# STM32H7RSxx register map
File version: 0.2
CPU: CM7 r0p1, little endian, MPU, FPU, 4 interrupt priority bits
Registers are 32-bit, read-write, reset 0x0 unless marked. A register's access mark holds for its fields unless they carry their own. Offsets are from the block's base; [hi:lo] are bit positions; {n}, {i} and the like mark numbered series; 'fields as' and 'values as' point back to an identical list; <NAME> marks a mode.

## RCC (part 2 of 3) — Reset and clock control
Base 0x58024400
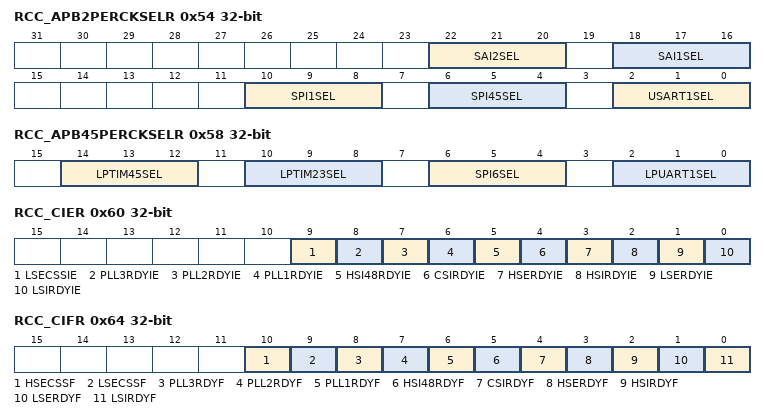
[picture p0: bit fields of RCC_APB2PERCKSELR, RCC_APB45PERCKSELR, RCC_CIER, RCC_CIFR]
0x54 RCC_APB2PERCKSELR — RCC APB2 peripherals kernel clock selection register
  [22:20] SAI2SEL — SAI2 kernel clock source selection Set and reset by software. If the selected clock is the external clock and this clock is stopped, it is not possible to switch to another clock. Refer to Clock switches and gating on page 437 for additional information. others: reserved, the kernel clock is disabled Note: I2S_CKIN is an external clock taken from a pin. spdifrx_symb_ck is the symbol clock generated by the spdifrx (see Figure 51).
    0=pll1_q_ck selected as SAI2 kernel clock (default after reset); 1=pll2_p_ck selected as SAI2 kernel clock; 2=pll3_p_ck selected as SAI2 kernel clock; 3=I2S_CKIN selected as SAI2 kernel clock; 4=per_ck selected as SAI2 kernel clock; 5=spdifrx_symb_ck selected as SAI2 kernel clock
  [18:16] SAI1SEL — SAI1 kernel clock source selection Set and reset by software. If the selected clock is the external clock and this clock is stopped, it is not possible to switch to another clock. Refer to Clock switches and gating on page 437 for additional information. others: reserved, the kernel clock is disabled Note: I2S_CKIN is an external clock taken from a pin.
    0=pll1_q_ck selected as SAI1 kernel clock (default after reset); 1=pll2_p_ck selected as SAI1 kernel clock; 2=pll3_p_ck selected as SAI1 kernel clock; 3=I2S_CKIN selected as SAI1 kernel clock; 4=per_ck selected as SAI1 kernel clock
  [10:8] SPI1SEL — SPI/I2S1 kernel clock source selection Set and reset by software. If the selected clock is the external clock and this clock is stopped, it is not be possible to switch to another clock. Refer to Clock switches and gating on page 437 for additional information. others: reserved, the kernel clock is disabled Note: I2S_CKIN is an external clock taken from a pin.
    0=pll1_q_ck selected as SPI/I2S1 and 7 kernel clock (default after reset); 1=pll2_p_ck selected as SPI/I2S1 and 7 kernel clock; 2=pll3_p_ck selected as SPI/I2S1 and 7 kernel clock; 3=I2S_CKIN selected as SPI/I2S1 and 7 kernel clock; 4=per_ck selected as SPI/I2S1,and 7 kernel clock
  [6:4] SPI45SEL — SPI4 and 5 kernel clock source selection Set and reset by software. others: reserved, the kernel clock is disabled
    0=pclk2 selected as kernel clock (default after reset); 1=pll2_q_ck is selected as kernel clock; 2=pll3_q_ck is selected as kernel clock; 3=hsi_ker_ck is selected as kernel clock; 4=csi_ker_ck is selected as kernel clock; 5=hse_ker_ck is selected as kernel clock
  [2:0] USART1SEL — USART1 kernel clock source selection Set and reset by software. others: reserved, the kernel clock is disabled
    0=pclk2 selected as kernel clock (default after reset); 1=pll2_q_ck selected as kernel clock; 2=pll3_q_ck selected as kernel clock; 3=hsi_ker_ck selected as kernel clock; 4=csi_ker_ck selected as kernel clock; 5=lse_ck selected as kernel clock
0x58 RCC_APB45PERCKSELR — RCC APB4,5 peripherals kernel clock selection register
  [14:12] LPTIM45SEL — LPTIM4, and LPTIM5 kernel clock source selection Set and reset by software. others: reserved, the kernel clock is disabled
    0=pclk4 selected as kernel peripheral clock (default after reset); 1=pll2_p_ck selected as kernel peripheral clock; 2=pll3_r_ck selected as kernel peripheral clock; 3=lse_ck selected as kernel peripheral clock; 4=lsi_ck selected as kernel peripheral clock; 5=per_ck selected as kernel peripheral clock
  [10:8] LPTIM23SEL — LPTIM2 and LPTIM3 kernel clock source selection Set and reset by software. others: reserved, the kernel clock is disabled
    values as LPTIM45SEL
  [6:4] SPI6SEL — SPI/I2S6 kernel clock source selection Set and reset by software. others: reserved, the kernel clock is disabled
    0=pclk4 selected as kernel peripheral clock (default after reset); 1=pll2_q_ck selected as kernel peripheral clock; 2=pll3_q_ck selected as kernel peripheral clock; 3=hsi_ker_ck selected as kernel peripheral clock; 4=csi_ker_ck selected as kernel peripheral clock; 5=hse_ker_ck selected as kernel peripheral clock
  [2:0] LPUART1SEL — LPUART1 kernel clock source selection Set and reset by software. others: reserved, the kernel clock is disabled
    0=pclk4 selected as kernel peripheral clock (default after reset); 1=pll2_q_ck selected as kernel peripheral clock; 2=pll3_q_ck selected as kernel peripheral clock; 3=hsi_ker_ck selected as kernel peripheral clock; 4=csi_ker_ck selected as kernel peripheral clock; 5=lse_ck selected as kernel peripheral clock
0x60 RCC_CIER — RCC clock source interrupt enable register
  [9] LSECSSIE — LSE clock security system interrupt enable Set and reset by software to enable/disable interrupt caused by the clock security system (CSS) on external 32 kHz oscillator.
    0=LSE CSS interrupt disabled (default after reset); 1=LSE CSS interrupt enabled
  [8] PLL3RDYIE — PLL3 ready interrupt enable Set and reset by software to enable/disable interrupt caused by PLL3 lock.
    0=PLL3 lock interrupt disabled (default after reset); 1=PLL3 lock interrupt enabled
  [7] PLL2RDYIE — PLL2 ready interrupt enable Set and reset by software to enable/disable interrupt caused by PLL2 lock.
    0=PLL2 lock interrupt disabled (default after reset); 1=PLL2 lock interrupt enabled
  [6] PLL1RDYIE — PLL1 ready interrupt enable Set and reset by software to enable/disable interrupt caused by PLL1 lock.
    0=PLL1 lock interrupt disabled (default after reset); 1=PLL1 lock interrupt enabled
  [5] HSI48RDYIE — HSI48 ready interrupt enable Set and reset by software to enable/disable interrupt caused by the HSI48 oscillator stabilization.
    0=HSI48 ready interrupt disabled (default after reset); 1=HSI48 ready interrupt enabled
  [4] CSIRDYIE — CSI ready interrupt enable Set and reset by software to enable/disable interrupt caused by the CSI oscillator stabilization.
    0=CSI ready interrupt disabled (default after reset); 1=CSI ready interrupt enabled
  [3] HSERDYIE — HSE ready interrupt enable Set and reset by software to enable/disable interrupt caused by the HSE oscillator stabilization.
    0=HSE ready interrupt disabled (default after reset); 1=HSE ready interrupt enabled
  [2] HSIRDYIE — HSI ready interrupt enable Set and reset by software to enable/disable interrupt caused by the HSI oscillator stabilization.
    0=HSI ready interrupt disabled (default after reset); 1=HSI ready interrupt enabled
  [1] LSERDYIE — LSE ready interrupt enable Set and reset by software to enable/disable interrupt caused by the LSE oscillator stabilization.
    0=LSE ready interrupt disabled (default after reset); 1=LSE ready interrupt enabled
  [0] LSIRDYIE — LSI ready interrupt enable Set and reset by software to enable/disable interrupt caused by the LSI oscillator stabilization.
    0=LSI ready interrupt disabled (default after reset); 1=LSI ready interrupt enabled
0x64 RCC_CIFR ro — RCC clock source interrupt flag register
  [10] HSECSSF — HSE clock security system interrupt flag Reset by software by writing HSECSSC bit. Set by hardware in case of HSE clock failure.
    0=no clock security interrupt caused by HSE clock failure (default after reset); 1=clock security interrupt caused by HSE clock failure
  [9] LSECSSF — LSE clock security system interrupt flag Reset by software by writing LSECSSC bit. Set by hardware when a failure is detected on the external 32 kHz oscillator and LSECSSIE is set.
    0=no failure detected on the external 32 kHz oscillator (default after reset); 1=failure detected on the external 32 kHz oscillator
  [8] PLL3RDYF — PLL3 ready interrupt flag Reset by software by writing PLL3RDYC bit. Set by hardware when the PLL3 locks and PLL3RDYIE is set.
    0=no clock ready interrupt caused by PLL3 lock (default after reset); 1=clock ready interrupt caused by PLL3 lock
  [7] PLL2RDYF — PLL2 ready interrupt flag Reset by software by writing PLL2RDYC bit. Set by hardware when the PLL2 locks and PLL2RDYIE is set.
    0=no clock ready interrupt caused by PLL2 lock (default after reset); 1=clock ready interrupt caused by PLL2 lock
  [6] PLL1RDYF — PLL1 ready interrupt flag Reset by software by writing PLL1RDYC bit. Set by hardware when the PLL1 locks and PLL1RDYIE is set.
    0=no clock ready interrupt caused by PLL1 lock (default after reset); 1=clock ready interrupt caused by PLL1 lock
  [5] HSI48RDYF — HSI48 ready interrupt flag Reset by software by writing HSI48RDYC bit. Set by hardware when the HSI48 clock becomes stable and HSI48RDYIE is set.
    0=no clock ready interrupt caused by the HSI48 oscillator (default after reset); 1=clock ready interrupt caused by the HSI48 oscillator
  [4] CSIRDYF — CSI ready interrupt flag Reset by software by writing CSIRDYC bit. Set by hardware when the CSI clock becomes stable and CSIRDYIE is set.
    0=no clock ready interrupt caused by the CSI (default after reset); 1=clock ready interrupt caused by the CSI
  [3] HSERDYF — HSE ready interrupt flag Reset by software by writing HSERDYC bit. Set by hardware when the HSE clock becomes stable and HSERDYIE is set.
    0=no clock ready interrupt caused by the HSE (default after reset); 1=clock ready interrupt caused by the HSE
  [2] HSIRDYF — HSI ready interrupt flag Reset by software by writing HSIRDYC bit. Set by hardware when the HSI clock becomes stable and HSIRDYIE is set.
    0=no clock ready interrupt caused by the HSI (default after reset); 1=clock ready interrupt caused by the HSI
  [1] LSERDYF — LSE ready interrupt flag Reset by software by writing LSERDYC bit. Set by hardware when the LSE clock becomes stable and LSERDYIE is set.
    0=no clock ready interrupt caused by the LSE (default after reset); 1=clock ready interrupt caused by the LSE
  [0] LSIRDYF — LSI ready interrupt flag Reset by software by writing LSIRDYC bit. Set by hardware when the LSI clock becomes stable and LSIRDYIE is set.
    0=no clock ready interrupt caused by the LSI (default after reset); 1=clock ready interrupt caused by the LSI
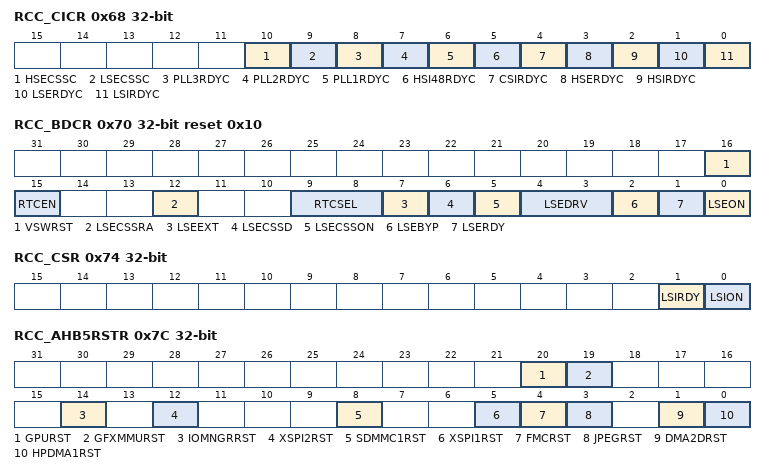
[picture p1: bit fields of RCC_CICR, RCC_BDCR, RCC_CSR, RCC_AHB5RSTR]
0x68 RCC_CICR — RCC clock source interrupt clear register
  [10] HSECSSC — HSE clock security system interrupt clear Set by software to clear HSECSSF. Reset by hardware when clear done.
    0=HSECSSF no effect (default after reset); 1=HSECSSF cleared
  [9] LSECSSC — LSE clock security system interrupt clear Set by software to clear LSECSSF. Reset by hardware when clear done.
    0=LSECSSF no effect (default after reset); 1=LSECSSF cleared
  [8] PLL3RDYC — PLL3 ready interrupt clear Set by software to clear PLL3RDYF. Reset by hardware when clear done.
    0=PLL3RDYF no effect (default after reset); 1=PLL3RDYF cleared
  [7] PLL2RDYC — PLL2 ready interrupt clear Set by software to clear PLL2RDYF. Reset by hardware when clear done.
    0=PLL2RDYF no effect (default after reset); 1=PLL2RDYF cleared
  [6] PLL1RDYC — PLL1 ready interrupt clear Set by software to clear PLL1RDYF. Reset by hardware when clear done.
    0=PLL1RDYF no effect (default after reset); 1=PLL1RDYF cleared
  [5] HSI48RDYC — HSI48 ready interrupt clear Set by software to clear HSI48RDYF. Reset by hardware when clear done.
    0=HSI48RDYF no effect (default after reset); 1=HSI48RDYF cleared
  [4] CSIRDYC — CSI ready interrupt clear Set by software to clear CSIRDYF. Reset by hardware when clear done.
    0=CSIRDYF no effect (default after reset); 1=CSIRDYF cleared
  [3] HSERDYC — HSE ready interrupt clear Set by software to clear HSERDYF. Reset by hardware when clear done.
    0=HSERDYF no effect (default after reset); 1=HSERDYF cleared
  [2] HSIRDYC — HSI ready interrupt clear Set by software to clear HSIRDYF. Reset by hardware when clear done.
    0=HSIRDYF no effect (default after reset); 1=HSIRDYF cleared
  [1] LSERDYC — LSE ready interrupt clear Set by software to clear LSERDYF. Reset by hardware when clear done.
    0=LSERDYF no effect (default after reset); 1=LSERDYF cleared
  [0] LSIRDYC — LSI ready interrupt clear Set by software to clear LSIRDYF. Reset by hardware when clear done.
    0=LSIRDYF no effect (default after reset); 1=LSIRDYF cleared
0x70 RCC_BDCR access per field reset 0x10 — RCC Backup domain control register
  [16] VSWRST rw — VSwitch domain software reset Set and reset by software. To generate a VSW reset, it is recommended to write this bit to 1, then back to 0.
    0=reset not activated (default after Backup domain reset); 1=generates a reset pulse, resetting the entire VSW domain
  [15] RTCEN rw — RTC clock enable Set and reset by software.
    0=rtc_ck disabled (default after Backup domain reset); 1=rtc_ck enabled
  [12] LSECSSRA rw — Re-Arm the LSECSS function Set by software. After a LSE failure detection, the software application can re-enable the LSECSS by writing this bit to 1. Reading this bit returns the written value. Prior to set this bit to 1, LSECSSON must be set to 0. Please refer to Section : CSS on LSE for details.
    0=Writing 0 has no effect (default after Backup domain reset); 1=Writing 1 generates a re-arm pulse for the LSECSS function
  [9:8] RTCSEL rw-once — RTC clock source selection Set by software to select the clock source for the RTC. These bits can be written only one time (except in case of failure detection on LSE). These bits must be written before LSECSSON is enabled. The VSWRST bit can be used to reset them, then it can be written one time again. If HSE is selected as RTC clock, this clock is lost when the system is in Stop mode or in case of a pin reset (NRST).
    0=no clock (default after Backup domain reset); 1=LSE selected as RTC clock; 2=LSI selected as RTC clock; 3=HSE divided by RTCPRE value selected as RTC clock
  [7] LSEEXT rw — low-speed external clock type in Bypass mode Set and reset by software to select the external clock type (analog or digital). The external clock must be enabled with the LSEON bit, to be used by the device. The LSEEXT bit can be written only if the LSE oscillator is disabled.
    0=LSE in analog mode (default after Backup domain reset); 1=LSE in digital mode (do not use if RTC is active)
  [6] LSECSSD ro — LSE clock security system failure detection Set by hardware to indicate when a failure has been detected by the clock security system on the external 32 kHz oscillator.
    0=no failure detected on 32 kHz oscillator (default after Backup domain reset); 1=failure detected on 32 kHz oscillator
  [5] LSECSSON rw — LSE clock security system enable Set by software to enable the clock security system on 32 kHz oscillator. LSECSSON must be enabled after LSE is enabled (LSEON enabled) and ready (LSERDY set by hardware) and after RTCSEL is selected. Once enabled, this bit can only be disabled, After a LSE failure detection (LSECSSD = 1). In that case the software must disable LSECSSON. After a back-up domain reset
    0=CSS on 32 kHz oscillator OFF (default after Backup domain reset); 1=CSS on 32 kHz oscillator ON
  [4:3] LSEDRV rw — LSE oscillator driving capability Set by software to select the driving capability of the LSE oscillator.
    0=lowest drive (default after Backup domain reset); 1=medium-low drive; 2=medium-high drive; 3=highest drive
  [2] LSEBYP rw — LSE oscillator bypass Set and reset by software to bypass oscillator in debug mode. This bit must not be written when the LSE is enabled (by LSEON) or ready (LSERDY = 1)
    0=LSE oscillator not bypassed (default after Backup domain reset); 1=LSE oscillator bypassed
  [1] LSERDY ro — LSE oscillator ready Set and reset by hardware to indicate when the LSE is stable. This bit needs 6 cycles of lse_ck clock to fall down after LSEON has been set to 0.
    0=LSE oscillator not ready (default after Backup domain reset); 1=LSE oscillator ready
  [0] LSEON rw — LSE oscillator enabled Set and reset by software.
    0=LSE oscillator OFF (default after Backup domain reset); 1=LSE oscillator ON
0x74 RCC_CSR access per field — RCC clock control and status register
  [1] LSIRDY ro — LSI oscillator ready Set and reset by hardware to indicate when the low-speed internal RC oscillator is stable. This bit needs 3 cycles of lsi_ck clock to fall down after LSION has been set to 0. This bit can be set even when LSION is not enabled if there is a request for LSI clock by the clock security system on LSE or by the low-speed watchdog or by the RTC.
    0=LSI clock is not ready (default after reset); 1=LSI clock is ready
  [0] LSION rw — LSI oscillator enable Set and reset by software.
    0=LSI is OFF (default after reset); 1=LSI is ON
0x7C RCC_AHB5RSTR — RCC AHB5 peripheral reset register
  [all] fields
    0=reset is released (default after reset); 1=reset is asserted
  [20] GPURST — GPU block reset Set and reset by software.
  [19] GFXMMURST — GFXMMU block reset Set and reset by software.
  [14] IOMNGRRST — XSPIM reset Set and reset by software.
  [12] XSPI2RST — XSPI2 and MCE2 blocks reset Set and reset by software. The hardware prevents writing this bit if XSPICKP = 1.
  [8] SDMMC1RST — SDMMC1 and DB_SDMMC1 blocks reset Set and reset by software.
  [5] XSPI1RST — XSPI1 and MCE1 blocks reset Set and reset by software. The hardware prevents writing this bit if XSPICKP = 1.
  [4] FMCRST — FMC and MCE3 blocks reset Set and reset by software. The hardware prevents writing this bit if FMCCKP = 1.
  [3] JPEGRST — JPEG block reset Set and reset by software.
  [1] DMA2DRST — DMA2D block reset Set and reset by software.
  [0] HPDMA1RST — HPDMA1 block reset Set and reset by software.
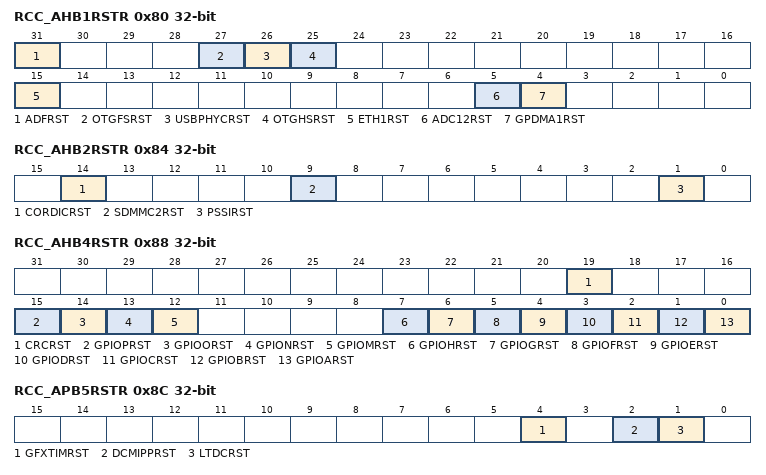
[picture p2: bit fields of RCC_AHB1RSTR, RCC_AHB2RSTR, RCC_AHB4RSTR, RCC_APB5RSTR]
0x80 RCC_AHB1RSTR — RCC AHB1 peripheral reset register
  [31] ADFRST — ADF block reset Set and reset by software.
    0=does not reset ADF block (default after reset); 1=resets ADF block
  [27] OTGFSRST — OTGFS block reset Set and reset by software.
    0=does not reset OTGFS block (default after reset); 1=resets OTGFS block
  [26] USBPHYCRST — USBPHYC block reset Set and reset by software.
    0=does not reset USBPHYC block (default after reset); 1=resets USBPHYC block
  [25] OTGHSRST — OTGHS block reset Set and reset by software.
    0=does not reset OTGHS block (default after reset); 1=resets OTGHS block
  [15] ETH1RST — ETH1 block reset Set and reset by software.
    0=does not reset ETH1 block (default after reset); 1=resets ETH1 block
  [5] ADC12RST — ADC1 and 2 blocks reset Set and reset by software.
    0=does not reset ADC1 and 2 blocks (default after reset); 1=resets ADC1 and 2 blocks
  [4] GPDMA1RST — GPDMA1 blocks reset Set and reset by software.
    0=does not reset GPDMA1 block (default after reset); 1=resets GPDMA1 block
0x84 RCC_AHB2RSTR — RCC AHB2 peripheral reset register
  [14] CORDICRST — CORDIC reset Set and reset by software.
    0=does not reset CORDIC block (default after reset); 1=resets CORDIC block
  [9] SDMMC2RST — SDMMC2 and SDMMC2 delay blocks reset Set and reset by software.
    0=does not reset SDMMC2 and SDMMC2 delay blocks (default after reset); 1=resets SDMMC2 and SDMMC2 delay blocks
  [1] PSSIRST — PSSI block reset Set and reset by software.
    0=does not reset PSSI block (default after reset); 1=resets PSSI block
0x88 RCC_AHB4RSTR — RCC AHB4 peripheral reset register
  [19] CRCRST — CRC block reset Set and reset by software.
    0=does not reset the CRC block (default after reset); 1=resets the CRC block
  [15] GPIOPRST — GPIOP block reset Set and reset by software.
    0=does not reset the GPIOP block (default after reset); 1=resets the GPIOP block
  [14] GPIOORST — GPIOO block reset Set and reset by software.
    0=does not reset the GPIOO block (default after reset); 1=resets the GPIOO block
  [13] GPIONRST — GPION block reset Set and reset by software.
    0=does not reset the GPION block (default after reset); 1=resets the GPION block
  [12] GPIOMRST — GPIOM block reset Set and reset by software.
    0=does not reset the GPIOM block (default after reset); 1=resets the GPIOM block
  [7] GPIOHRST — GPIOH block reset Set and reset by software.
    0=does not reset the GPIOH block (default after reset); 1=resets the GPIOH block
  [6] GPIOGRST — GPIOG block reset Set and reset by software.
    0=does not reset the GPIOG block (default after reset); 1=resets the GPIOG block
  [5] GPIOFRST — GPIOF block reset Set and reset by software.
    0=does not reset the GPIOF block (default after reset); 1=resets the GPIOF block
  [4] GPIOERST — GPIOE block reset Set and reset by software.
    0=does not reset the GPIOE block (default after reset); 1=resets the GPIOE block
  [3] GPIODRST — GPIOD block reset Set and reset by software.
    0=does not reset the GPIOD block (default after reset); 1=resets the GPIOD block
  [2] GPIOCRST — GPIOC block reset Set and reset by software.
    0=does not reset the GPIOC block (default after reset); 1=resets the GPIOC block
  [1] GPIOBRST — GPIOB block reset Set and reset by software.
    0=does not reset the GPIOB block (default after reset); 1=resets the GPIOB block
  [0] GPIOARST — GPIOA block reset Set and reset by software.
    0=does not reset the GPIOA block (default after reset); 1=resets the GPIOA block
0x8C RCC_APB5RSTR — RCC APB5 peripheral reset register
  [4] GFXTIMRST — GFXTIM block reset Set and reset by software.
    0=does not reset the GFXTIM block (default after reset); 1=resets the GFXTIM block
  [2] DCMIPPRST — DCMIPP block reset Set and reset by software.
    0=does not reset the DCMIPP block (default after reset); 1=resets the DCMIPP block
  [1] LTDCRST — LTDC block reset Set and reset by software.
    0=does not reset the LTDC block (default after reset); 1=resets the LTDC block
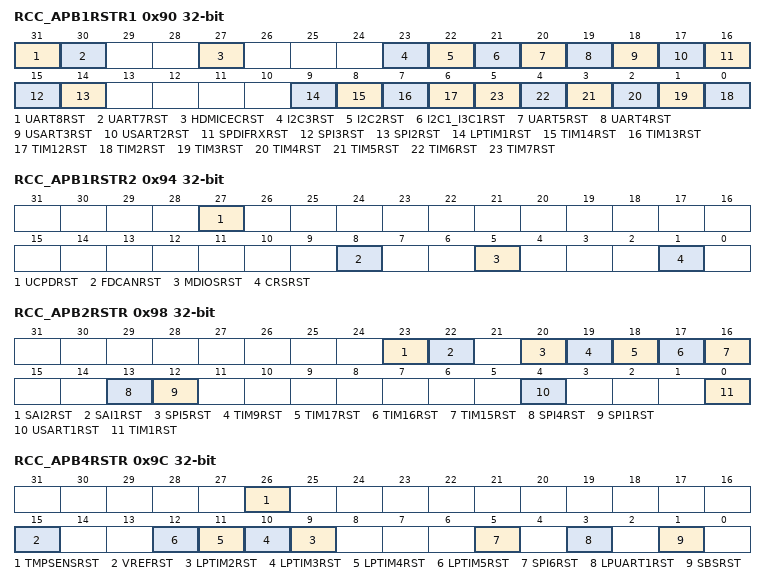
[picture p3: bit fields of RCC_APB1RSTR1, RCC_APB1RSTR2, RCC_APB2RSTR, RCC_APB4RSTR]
0x90 RCC_APB1RSTR1 — RCC APB1 peripheral reset register 1
  [31] UART8RST — UART8 block reset Set and reset by software.
    0=does not reset the UART8 block (default after reset); 1=resets the UART8 block
  [30] UART7RST — UART7 block reset Set and reset by software.
    0=does not reset the UART7 block (default after reset); 1=resets the UART7 block
  [27] HDMICECRST — HDMI-CEC block reset Set and reset by software.
    0=does not reset the HDMI-CEC block (default after reset); 1=resets the HDMI-CEC block
  [23] I2C3RST — I2C3 block reset Set and reset by software.
    0=does not reset the I2C3 block (default after reset); 1=resets the I2C3 block
  [22] I2C2RST — I2C2 block reset Set and reset by software.
    0=does not reset the I2C2 block (default after reset); 1=resets the I2C2 block
  [21] I2C1_I3C1RST — I2C1/I3C1 block reset Set and reset by software.
    0=does not reset the I2C1/I3C1 block (default after reset); 1=resets the I2C1/I3C1 block
  [20] UART5RST — UART5 block reset Set and reset by software.
    0=does not reset the UART5 block (default after reset); 1=resets the UART5 block
  [19] UART4RST — UART4 block reset Set and reset by software.
    0=does not reset the UART4 block (default after reset); 1=resets the UART4 block
  [18] USART3RST — USART3 block reset Set and reset by software.
    0=does not reset the USART3 block (default after reset); 1=resets the USART3 block
  [17] USART2RST — USART2 block reset Set and reset by software.
    0=does not reset the USART2 block (default after reset); 1=resets the USART2 block
  [16] SPDIFRXRST — SPDIFRX block reset Set and reset by software.
    0=does not reset the SPDIFRX block (default after reset); 1=resets the SPDIFRX block
  [15] SPI3RST — SPI2S3 block reset Set and reset by software.
    0=does not reset the SPI2S3 block (default after reset); 1=resets the SPI2S3 block
  [14] SPI2RST — SPI2S2 block reset Set and reset by software.
    0=does not reset the SPI2S2 block (default after reset); 1=resets the SPI2S2 block
  [9] LPTIM1RST — LPTIM1 block reset Set and reset by software.
    0=does not reset the LPTIM1 block (default after reset); 1=resets the LPTIM1 block
  [8] TIM14RST — TIM14 block reset Set and reset by software.
    0=does not reset the TIM14 block (default after reset); 1=resets the TIM14 block
  [7] TIM13RST — TIM13 block reset Set and reset by software.
    0=does not reset the TIM13 block (default after reset); 1=resets the TIM13 block
  [6] TIM12RST — TIM12 block reset Set and reset by software.
    0=does not reset the TIM12 block (default after reset); 1=resets the TIM12 block
  [n-2] TIM{n}RST (n=2..7) — TIM{n} block reset Set and reset by software.
    0=does not reset the TIM{n} block (default after reset); 1=resets the TIM{n} block
0x94 RCC_APB1RSTR2 — RCC APB1 peripheral reset register 2
  [27] UCPDRST — UCPD block reset Set and reset by software.
    0=does not reset the UCPD block (default after reset); 1=resets the UCPD block
  [8] FDCANRST — FDCAN block reset Set and reset by software.
    0=does not reset the FDCAN block (default after reset); 1=resets the FDCAN block
  [5] MDIOSRST — MDIOS block reset Set and reset by software.
    0=does not reset the MDIOS block (default after reset); 1=resets the MDIOS block
  [1] CRSRST — clock recovery system reset Set and reset by software.
    0=does not reset CRS (default after reset); 1=resets CRS
0x98 RCC_APB2RSTR — RCC APB2 peripheral reset register
  [23] SAI2RST — SAI2 block reset Set and reset by software.
    0=does not reset the SAI2 (default after reset); 1=resets the SAI2
  [22] SAI1RST — SAI1 block reset Set and reset by software.
    0=does not reset the SAI1 (default after reset); 1=resets the SAI1
  [20] SPI5RST — SPI5 block reset Set and reset by software.
    0=does not reset the SPI5 block (default after reset); 1=resets the SPI5 block
  [19] TIM9RST — TIM9 block reset Set and reset by software.
    0=does not reset the TIM9 block (default after reset); 1=resets the TIM9 block
  [18] TIM17RST — TIM17 block reset Set and reset by software.
    0=does not reset the TIM17 block (default after reset); 1=resets the TIM17 block
  [17] TIM16RST — TIM16 block reset Set and reset by software.
    0=does not reset the TIM16 block (default after reset); 1=resets the TIM16 block
  [16] TIM15RST — TIM15 block reset Set and reset by software.
    0=does not reset the TIM15 block (default after reset); 1=resets the TIM15 block
  [13] SPI4RST — SPI4 block reset Set and reset by software.
    0=does not reset the SPI4 block (default after reset); 1=resets the SPI4 block
  [12] SPI1RST — SPI2S1 block reset Set and reset by software.
    0=does not reset the SPI2S1 block (default after reset); 1=resets the SPI2S1 block
  [4] USART1RST — USART1 block reset Set and reset by software.
    0=does not reset the USART1 block (default after reset); 1=resets the USART1 block
  [0] TIM1RST — TIM1 block reset Set and reset by software.
    0=does not reset the TIM1 block (default after reset); 1=resets the TIM1 block
0x9C RCC_APB4RSTR — RCC APB4 peripheral reset register
  [26] TMPSENSRST — TMPSENS block reset Set and reset by software.
    0=does not reset the TMPSENS block (default after reset); 1=resets the TMPSENS block
  [15] VREFRST — VREF block reset Set and reset by software.
    0=does not reset the VREF block (default after reset); 1=resets the VREF block
  [n+7] LPTIM{n}RST (n=2..5) — LPTIM{n} block reset Set and reset by software.
    0=does not reset the LPTIM{n} block (default after reset); 1=resets the LPTIM{n} block
  [5] SPI6RST — SPI/I2S6 block reset Set and reset by software.
    0=does not reset the SPI/I2S6 block (default after reset); 1=resets the SPI/I2S6 block
  [3] LPUART1RST — LPUART1 block reset Set and reset by software.
    0=does not reset the LPUART1 block (default after reset); 1=resets the LPUART1 block
  [1] SBSRST — SBS block reset Set and reset by software.
    0=does not reset the SBS block (default after reset); 1=resets the SBS block
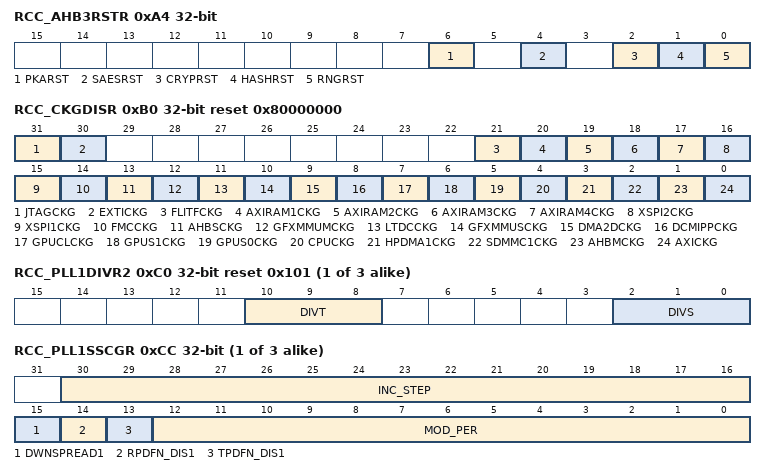
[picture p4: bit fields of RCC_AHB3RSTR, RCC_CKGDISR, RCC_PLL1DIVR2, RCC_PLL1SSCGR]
0xA4 RCC_AHB3RSTR — RCC AHB3 peripheral reset register
  [6] PKARST — PKA block reset Set and reset by software.
    0=does not reset PKA block (default after reset); 1=resets PKA block
  [4] SAESRST — SAES block reset Set and reset by software.
    0=does not reset SAES block (default after reset); 1=resets SAES block
  [2] CRYPRST — CRYP block reset Set and reset by software.
    0=does not reset CRYP block (default after reset); 1=resets CRYP block
  [1] HASHRST — HASH block reset Set and reset by software.
    0=does not reset HASH block (default after reset); 1=resets HASH block
  [0] RNGRST — random number generator block reset Set and reset by software.
    0=does not reset RNG block (default after reset); 1=resets RNG block
0xB0 RCC_CKGDISR reset 0x80000000 — RCC AXI clocks gating disable register
  [31] JTAGCKG — JTAG automatic clock gating disabling This bit is set and reset by software.
    0=The clock gating is enabled. The clock is disabled except if a JTAG connection has been detected 1: The clock gating is disabled. The clock is always enabled. (default after reset)
  [30] EXTICKG — EXTI clock gating disable This bit is set and reset by software.
    0=The clock gating is enabled. The clock is enabled after an event detection and stopped again when the event flag is cleared. (default after reset); 1=The clock gating is disabled. The clock is always enabled.
  [21] FLITFCKG — AXI slave Flash interface (FLIFT) clock gating disable This bit is set and reset by software.
    0=The clock gating is enabled. The clock of the AXI slave port connected to the FLITF is enabled on bus transaction request. (default after reset); 1=The clock gating is disabled. The clock is always enabled.
  [20] AXIRAM1CKG — AXI slave SRAM1 / error code correction (ECC) clock gating disable This bit is set and reset by software.
    0=The clock gating is enabled. The clock of the AXI slave port connected to the SRAM1 is enabled on bus transaction request. (default after reset); 1=The clock gating is disabled. The clock is always enabled.
  [19] AXIRAM2CKG — AXI slave SRAM2 clock gating disable This bit is set and reset by software.
    0=The clock gating is enabled. The clock of the AXI slave port connected to the SRAM2 is enabled on bus transaction request. (default after reset); 1=The clock gating is disabled. The clock is always enabled.
  [18] AXIRAM3CKG — AXI matrix slave SRAM3 clock gating disable This bit is set and reset by software.
    0=The clock gating is enabled. The clock of the AXI slave port connected to the SRAM3 is enabled on bus transaction request. (default after reset); 1=The clock gating is disabled. The clock is always enabled.
  [17] AXIRAM4CKG — AXI matrix slave SRAM4 clock gating disable This bit is set and reset by software.
    0=The clock gating is enabled. The clock of the AXI slave port connected to the SRAM4 is enabled on bus transaction request. (default after reset); 1=The clock gating is disabled. The clock is always enabled.
  [16] XSPI2CKG — AXI slave XSPI2 and MCE2 clock gating disable This bit is set and reset by software.
    0=The clock gating is enabled. The clock of the AXI slave port connected to the XSPI2 and MCE2 is enabled on bus transaction request. (default after reset); 1=The clock gating is disabled. The clock is always enabled.
  [15] XSPI1CKG — AXI slave XSPI1 and MCE1 clock gating disable This bit is set and reset by software.
    0=The clock gating is enabled. The clock of the AXI slave port connected to the XSPI1 and MCE1 is enabled on bus transaction request. (default after reset); 1=The clock gating is disabled. The clock is always enabled.
  [14] FMCCKG — AXI slave FMC and MCE3 clock gating disable This bit is set and reset by software.
    0=The clock gating is enabled. The clock of the AXI slave port connected to the FMC and MCE3 is enabled on bus transaction request. (default after reset); 1=The clock gating is disabled. The clock is always enabled.
  [13] AHBSCKG — AXI slave AHB clock gating disable This bit is set and reset by software.
    0=The clock gating is enabled. The AXI matrix slave AHB clock is enabled on bus transaction request. (default after reset); 1=The clock gating is disabled. The clock is always enabled
  [12] GFXMMUMCKG — AXI master GFXMMU clock gating disable This bit is set and reset by software.
    0=The clock gating is enabled. The clock of the AXI master port connected to the GFXMMU is enabled on bus transaction request. (default after reset); 1=The clock gating is disabled. The clock is always enabled
  [11] LTDCCKG — AXI master LTDC clock gating disable This bit is set and reset by software.
    0=The clock gating is enabled. The clock of the AXI master port connected to the LTDC is enabled on bus transaction request. (default after reset); 1=The clock gating is disabled. The clock is always enabled.
  [10] GFXMMUSCKG — AXI matrix slave GFXMMU clock gating disable This bit is set and reset by software.
    0=The clock gating is enabled. The clock of the AXI slave port connected to the GFXMMU is enabled on bus transaction request. (default after reset); 1=The clock gating is disabled. The clock is always enabled
  [9] DMA2DCKG — AXI master DMA2D clock gating disable This bit is set and reset by software.
    0=The clock gating is enabled. The clock of the AXI master port connected to the DMA2D is enabled on bus transaction request. (default after reset); 1=The clock gating is disabled. The clock is always enabled
  [8] DCMIPPCKG — AXI master DCMIPP clock gating disable This bit is set and reset by software.
    0=The clock gating is enabled. The clock of the AXI master port connected to the DCMIPP is enabled on bus transaction request. (default after reset); 1=The clock gating is disabled. The clock is always enabled.
  [7] GPUCLCKG — AXI master cache GPU clock gating disable This bit is set and reset by software.
    0=The clock gating is enabled. The clock of the AXI master port connected to the GPU I-Cache is enabled on bus transaction request. (default after reset); 1=The clock gating is disabled. The clock is always enabled.
  [6] GPUS1CKG — AXI master 1 GPU clock gating disable This bit is set and reset by software.
    0=The clock gating is enabled. The clock of the AXI master port connected to the GPU port 1 is enabled on bus transaction request. (default after reset); 1=The clock gating is disabled. The clock is always enabled.
  [5] GPUS0CKG — AXI master 0 GPU clock gating disable This bit is set and reset by software.
    0=The clock gating is enabled. The clock of the AXI master port connected to the GPU port 0 is enabled on bus transaction request. (default after reset); 1=The clock gating is disabled. The clock is always enabled.
  [4] CPUCKG — AXI master CPU clock gating disable This bit is set and reset by software.
    0=The clock gating is enabled. The clock of the AXI master port connected to the CPU is enabled on bus transaction request. (default after reset); 1=The clock gating is disabled. The clock is always enabled.
  [3] HPDMA1CKG — AXI master HPDMA1 clock gating disable This bit is set and reset by software.
    0=The clock gating is enabled. The clock of the AXI master port connected to the HPDMA1 is enabled on bus transaction request. (default after reset); 1=The clock gating is disabled. The clock is always enabled
  [2] SDMMC1CKG — AXI master SDMMC1 clock gating disable This bit is set and reset by software.
    0=The clock gating is enabled. The clock of the AXI master port connected to SDMMC1 is enabled on bus transaction request. (default after reset); 1=The clock gating is disabled. The clock is always enabled.
  [1] AHBMCKG — AXI master AHB clock gating disable This bit is set and reset by software.
    0=The clock gating is enabled. The clock of the AXI master port connected to the AHB interconnect is enabled on bus transaction request. (default after reset); 1=The clock gating is disabled. The clock is always enabled.
  [0] AXICKG — AXI interconnect matrix clock gating disable This bit is set and reset by software.
    0=The clock gating is enabled. The AXI interconnect matrix clock is enabled on bus transaction request. (default after reset); 1=The clock gating is disabled. The clock is always enabled
{0xBC+4i} RCC_PLL{i}DIVR2 reset 0x101 (i=1..3) — RCC PLL{i} dividers configuration register 2
  [10:8] DIVT — PLL{i} DIVT division factor Set and reset by software to control the frequency of the pll{i}_t_ck clock. This post-divider performs divisions with 50% duty-cycle. The duty-cycle of 50% is guaranteed only in the following conditions: With VCOL, if (DIVT+1) is even, With VCOH, for all DIVT values These bits can be written only when the PLL{i}DIVTEN = 0.
    0=pll{i}_t_ck = vco{i}_ck; 1=pll{i}_t_ck = vco{i}_ck / 2 (default after reset); {v}=pll{i}_t_ck = vco{i}_ck / {v+1} (v=2..7)
  [2:0] DIVS — PLL{i} DIVS division factor Set and reset by software to control the frequency of the pll{i}_s_ck clock. This post-divider performs divisions with 50% duty-cycle. The duty-cycle of 50% is guaranteed only in the following conditions: With VCOL, if (DIVS+1) is even, With VCOH, for all DIVS values These bits can be written only when the PLL{i}DIVSEN = 0.
    0=pll{i}_s_ck = vco{i}_ck; 1=pll{i}_s_ck = vco{i}_ck / 2 (default after reset); {v}=pll{i}_s_ck = vco{i}_ck / {v+1} (v=2..7)
{0xC8+4i} RCC_PLL{i}SSCGR (i=1..3) — RCC PLL{i} Spread Spectrum Clock Generator register
  [30:16] INC_STEP — Modulation Depth Adjustment for PLL{i} Set and reset by software to adjust the modulation depth of the clock spreading generator.
  [15] DWNSPREAD{i} — Spread spectrum clock generator mode for PLL{i} Set and reset by software to select the clock spreading mode.
    0=Center-spread modulation selected (default after reset); 1=Down-spread modulation selected
  [14] RPDFN_DIS{i} — Dithering RPDF noise control for PLL{i} Set and reset by software. This bit is used to enable or disable the injection of a dithering noise into the SSCG modulator. This dithering noise is generated using a rectangular probability density function.
    0=Dithering noise injection enabled (default after reset); 1=Dithering noise injection disabled
  [13] TPDFN_DIS{i} — Dithering TPDF noise control for PLL{i} Set and reset by software. This bit is used to enable or disable the injection of a dithering noise into the SSCG modulator. This dithering noise is generated using a triangular probability density function.
    values as RPDFN_DIS{i}
  [12:0] MOD_PER — Modulation Period Adjustment for PLL{i} Set and reset by software to adjust the modulation period of the clock spreading generator.
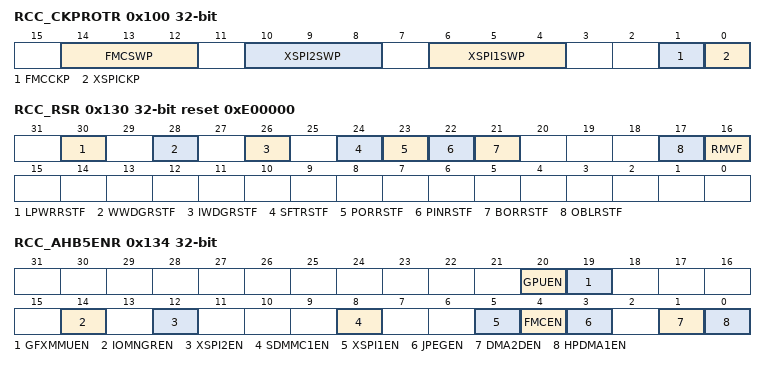
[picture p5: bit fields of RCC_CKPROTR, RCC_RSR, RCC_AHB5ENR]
0x100 RCC_CKPROTR access per field — RCC clock protection register
  [14:12] FMCSWP ro — FMC kernel clock switch position Set by hardware. This field can be used to verify the real position of FMC kernel switch selector.
    0=The switch is in neutral mode and output clock is gated (default after reset); 1=The switch is selecting hclk5; 2=The switch is selecting pll1_q_ck; 3=The switch is selecting pll2_r_ck; 4=The switch is selecting hsi_ker_ck; 5=The switch is in recovery position (hclk5/4)
  [10:8] XSPI2SWP ro — XSPI2 kernel clock switch position Set by hardware. This field can be used to verify the real position of XSPI2 kernel switch selector.
    0=The switch is in neutral mode and output clock is gated (default after reset); 1=The switch is selecting hclk5; 2=The switch is selecting pll2_s_ck; 3=The switch is selecting pll2_t_ck; 4=The switch is in recovery position (hclk5/4)
  [6:4] XSPI1SWP ro — XSPI1 kernel clock switch position Set by hardware. This field can be used to verify the real position of XSPI2 kernel switch selector.
    values as XSPI2SWP
  [1] FMCCKP rw — FMC clock protection Set and cleared by software. When set to 1, this bit prevents disabling accidentally the FMC. The following fields cannot be modified when this bit is set to 1: PLL1ON, PLL2ON, PLL1DIVQEN, PLL2DIVREN, HSEON, HSION, CSION, FMCEN, FMCLPEN, FMCRST.
    0=Clock protection is disabled (default after reset); 1=Clock protection is enabled
  [0] XSPICKP rw — XSPI clock protection Set and cleared by software. When set to 1, this bit prevents disabling accidentally the XSPIs. The following fields cannot be modified when this bit is set to 1: PLL2ON, PLL2DIVSEN, PLL2DIVTEN, HSEON, HSION, CSION, XSPIxEN, OCTOSPIxLPEN, OCTOSPIxRST.
    values as FMCCKP
0x130 RCC_RSR access per field reset 0xE00000 — RCC Reset status register
  [30] LPWRRSTF ro — reset due to illegal Stop or Standby flag Reset by software by writing the RMVF bit. Set by hardware when the CPU goes erroneously in Stop or Standby mode,
    0=no illegal reset occurred (default after power-on reset); 1=illegal Stop or Standby reset occurred
  [28] WWDGRSTF ro — window watchdog reset flag <sup>(1)</sup> Reset by software by writing the RMVF bit. Set by hardware when a window watchdog reset occurs.
    0=no window watchdog reset occurred from WWDG (default after power-on reset); 1=window watchdog reset occurred from WWDG
  [26] IWDGRSTF ro — independent watchdog reset flag <sup>(1)</sup> Reset by software by writing the RMVF bit. Set by hardware when an independent watchdog reset occurs.
    0=no independent watchdog reset occurred (default after power-on reset); 1=independent watchdog reset occurred
  [24] SFTRSTF ro — system reset from CPU reset flag <sup>(1)</sup> Reset by software by writing the RMVF bit. Set by hardware when the system reset is due to CPU.The CPU can generate a system reset by writing SYSRESETREQ bit of AIRCR register of the core M7.
    0=no CPU software reset occurred (default after power-on reset); 1=a system reset has been generated by the CPU
  [23] PORRSTF ro — POR/PDR reset flag <sup>(1)</sup> Reset by software by writing the RMVF bit. Set by hardware when a POR/PDR reset occurs.
    0=no POR/PDR reset occurred; 1=POR/PDR reset occurred (default after power-on reset)
  [22] PINRSTF ro — pin reset flag (NRST) <sup>(1)</sup> Reset by software by writing the RMVF bit. Set by hardware when a reset from pin occurs.
    0=no reset from pin occurred; 1=reset from pin occurred (default after power-on reset)
  [21] BORRSTF ro — BOR reset flag <sup>(1)</sup> Reset by software by writing the RMVF bit. Set by hardware when a BOR reset occurs (pwr_bor_rst).
    0=no BOR reset occurred; 1=BOR reset occurred (default after power-on reset)
  [17] OBLRSTF ro — Option byte loading reset flag <sup>(1)</sup> Reset by software by the RMVF bit. Set by hardware when a reset from the option byte loading occurs.
    0=No reset from option byte loading occurred; 1=Reset from option byte loading occurred
  [16] RMVF rw — remove reset flag Set and reset by software to reset the value of the reset flags.
    0=reset of the reset flags not activated (default after power-on reset); 1=resets the value of the reset flags
0x134 RCC_AHB5ENR — RCC AHB5 clock enable register
  [20] GPUEN — GPU peripheral clock enable Set and reset by software.
    0=GPU peripheral clock disabled (default after reset); 1=GPU peripheral clock enabled
  [19] GFXMMUEN — GFXMMU peripheral clock enable Set and reset by software.
    0=GFXMMU peripheral clock disabled (default after reset); 1=GFXMMU peripheral clock enabled
  [14] IOMNGREN — XSPIM peripheral clock enable Set and reset by software.
    0=XSPIM peripheral clock disabled (default after reset); 1=XSPIM peripheral clock enabled
  [12] XSPI2EN — XSPI2 and MCE2 peripheral clocks enable Set and reset by software. The hardware prevents writing this bit if XSPICKP = 1.
    0=XSPI2 and MCE2 peripheral clocks disabled (default after reset); 1=XSPI2 and MCE2 peripheral clocks enabled
  [8] SDMMC1EN — SDMMC1 and DB_SDMMC1 peripheral clocks enable Set and reset by software.
    0=SDMMC1 and DB_SDMMC1 peripheral clocks disabled (default after reset); 1=SDMMC1 and DB_SDMMC1 peripheral clocks enabled
  [5] XSPI1EN — XSPI1 and MCE1 peripheral clocks enable Set and reset by software. The hardware prevents writing this bit if XSPICKP = 1.
    0=XSPI1 and MCE1 peripheral clocks disabled (default after reset); 1=XSPI1 and MCE1 peripheral clocks enabled
  [4] FMCEN — FMC and MCE3 peripheral clocks enable Set and reset by software. The hardware prevents writing this bit if FMCCKP = 1. The peripheral clocks of the FMC are the kernel clock selected by FMCSEL, and the hclk5 bus interface clock.
    0=FMC and MCE3 peripheral clocks disabled (default after reset); 1=FMC and MCE3 peripheral clocks enabled
  [3] JPEGEN — JPEG peripheral clock enable Set and reset by software.
    0=JPEG peripheral clock disabled (default after reset); 1=JPEG peripheral clock enabled
  [1] DMA2DEN — DMA2D peripheral clock enable Set and reset by software.
    0=DMA2D peripheral clock disabled (default after reset); 1=DMA2D peripheral clock enabled
  [0] HPDMA1EN — HPDMA1 peripheral clock enable Set and reset by software.
    0=HPDMA1 peripheral clock disabled (default after reset); 1=HPDMA1 peripheral clock enabled
